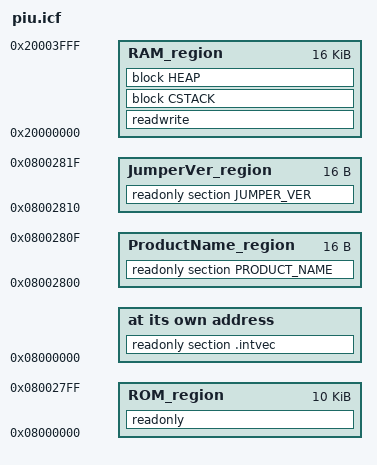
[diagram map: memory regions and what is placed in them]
/*###ICF### Section handled by ICF editor, don't touch! ****/
/*-Editor annotation file-*/
/* IcfEditorFile="$TOOLKIT_DIR$\config\ide\IcfEditor\cortex_v1_0.xml" */
/*-Specials-*/
define symbol __ICFEDIT_intvec_start__ = 0x08000000;
/*-Memory Regions-*/
define symbol __ICFEDIT_region_ROM_start__ = 0x08000000;
define symbol __ICFEDIT_region_ROM_end__   = 0x080027FF;
define symbol __ICFEDIT_region_RAM_start__ = 0x20000000;
define symbol __ICFEDIT_region_RAM_end__   = 0x20003FFF;

/*-ROM region to store settings-*/
define symbol __USEREDIT_REGION_ProductName_start__ = 0x08002800;
define symbol __USEREDIT_REGION_ProductName_end__ = 0x0800280F;

define symbol __USEREDIT_REGION_JumperVer_start__ = 0x08002810;
define symbol __USEREDIT_REGION_JumperVer_end__ = 0x0800281F;

/*-Sizes-*/
define symbol __ICFEDIT_size_cstack__ = 0x400;
define symbol __ICFEDIT_size_heap__   = 0x200;
/**** End of ICF editor section. ###ICF###*/

define memory mem with size = 4G;
define region ROM_region   = mem:[from __ICFEDIT_region_ROM_start__   to __ICFEDIT_region_ROM_end__];
define region RAM_region   = mem:[from __ICFEDIT_region_RAM_start__   to __ICFEDIT_region_RAM_end__];

define region ProductName_region = mem:[from __USEREDIT_REGION_ProductName_start__ to __USEREDIT_REGION_ProductName_end__];
define region JumperVer_region = mem:[from __USEREDIT_REGION_JumperVer_start__ to __USEREDIT_REGION_JumperVer_end__];
define block CSTACK    with alignment = 8, size = __ICFEDIT_size_cstack__   { };
define block HEAP      with alignment = 8, size = __ICFEDIT_size_heap__     { };

initialize by copy { readwrite };
do not initialize  { section .noinit };

place at address mem:__ICFEDIT_intvec_start__ { readonly section .intvec };

place in ROM_region   { readonly };
place in RAM_region   { readwrite,
                        block CSTACK, block HEAP };

/*-place Information in ROM-*/
place in ProductName_region {readonly section PRODUCT_NAME};
place in JumperVer_region {readonly section JUMPER_VER};

export symbol __ICFEDIT_region_RAM_start__;
export symbol __ICFEDIT_region_RAM_end__;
